# ESP32-P4 register map
Vendor: ESPRESSIF SYSTEMS (SHANGHAI) CO., LTD.; Series: ESP32 P-Series; File version: 3
CPU: RV32IMAFC r0p0, little endian, no MPU, FPU, 0 interrupt priority bits
Address unit: 32 bits
Registers are 32-bit, read-write, reset 0x0 unless marked. A register's access mark holds for its fields unless they carry their own. Offsets are from the block's base; [hi:lo] are bit positions; lines under a group give offsets from that group; {n}, {i} and the like mark numbered series; 'fields as' and 'values as' point back to an identical list.

## MEMSPI3 — Memory SPI 3
Base 0x5008F000
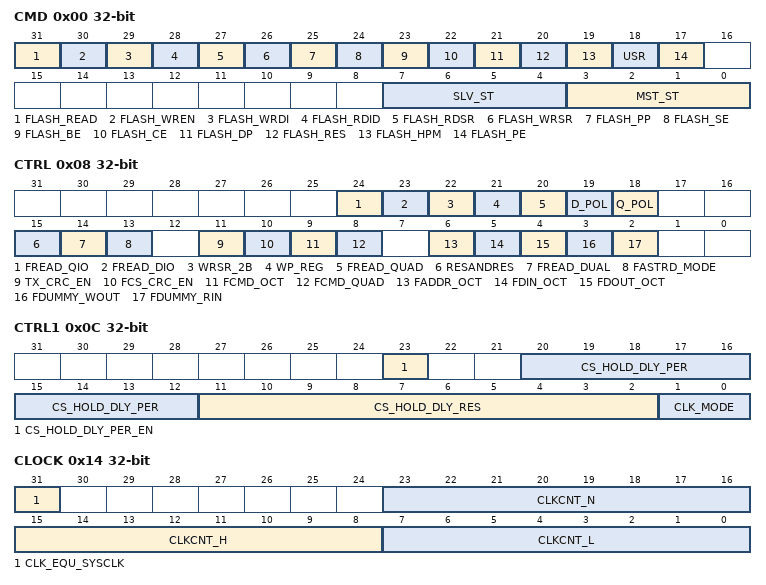
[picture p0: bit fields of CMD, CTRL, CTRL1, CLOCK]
0x00 CMD access per field
  [31] FLASH_READ rw, [30] FLASH_WREN rw, [29] FLASH_WRDI rw, [28] FLASH_RDID rw, [27] FLASH_RDSR rw, [26] FLASH_WRSR rw, [25] FLASH_PP rw, [24] FLASH_SE rw, [23] FLASH_BE rw, [22] FLASH_CE rw, [21] FLASH_DP rw, [20] FLASH_RES rw, [19] FLASH_HPM rw, [18] USR rw, [17] FLASH_PE rw, [7:4] SLV_ST ro, [3:0] MST_ST ro
0x04 ADDR
  [31:0] USR_ADDR_VALUE
0x08 CTRL
  [24] FREAD_QIO, [23] FREAD_DIO, [22] WRSR_2B, [21] WP_REG, [20] FREAD_QUAD, [19] D_POL, [18] Q_POL, [15] RESANDRES, [14] FREAD_DUAL, [13] FASTRD_MODE, [11] TX_CRC_EN, [10] FCS_CRC_EN, [9] FCMD_OCT, [8] FCMD_QUAD, [6] FADDR_OCT, [5] FDIN_OCT, [4] FDOUT_OCT, [3] FDUMMY_WOUT, [2] FDUMMY_RIN
0x0C CTRL1
  [23] CS_HOLD_DLY_PER_EN, [20:12] CS_HOLD_DLY_PER, [11:2] CS_HOLD_DLY_RES, [1:0] CLK_MODE
0x10 CTRL2 wo
  [31] SYNC_RESET
0x14 CLOCK
  [31] CLK_EQU_SYSCLK, [23:16] CLKCNT_N, [15:8] CLKCNT_H, [7:0] CLKCNT_L
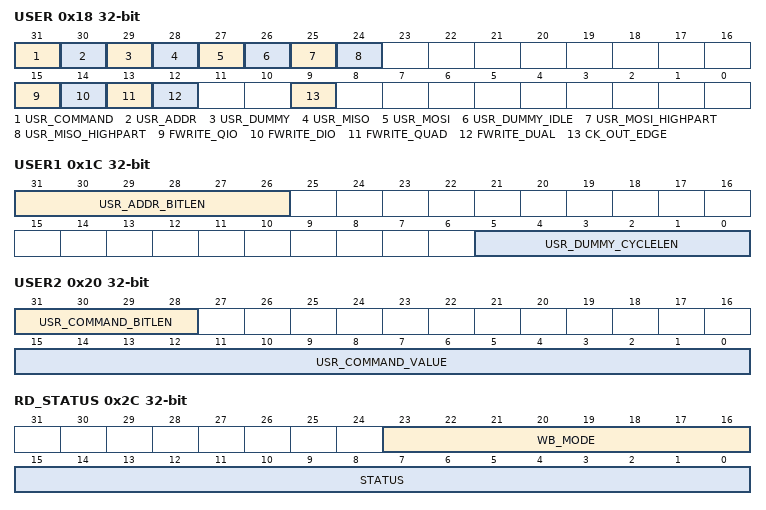
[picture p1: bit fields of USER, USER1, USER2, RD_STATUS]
0x18 USER
  [31] USR_COMMAND, [30] USR_ADDR, [29] USR_DUMMY, [28] USR_MISO, [27] USR_MOSI, [26] USR_DUMMY_IDLE, [25] USR_MOSI_HIGHPART, [24] USR_MISO_HIGHPART, [15] FWRITE_QIO, [14] FWRITE_DIO, [13] FWRITE_QUAD, [12] FWRITE_DUAL, [9] CK_OUT_EDGE
0x1C USER1
  [31:26] USR_ADDR_BITLEN, [5:0] USR_DUMMY_CYCLELEN
0x20 USER2
  [31:28] USR_COMMAND_BITLEN, [15:0] USR_COMMAND_VALUE
0x24 MOSI_DLEN
  [9:0] USR_MOSI_DBITLEN
0x28 MISO_DLEN
  [9:0] USR_MISO_DBITLEN
0x2C RD_STATUS
  [23:16] WB_MODE, [15:0] STATUS
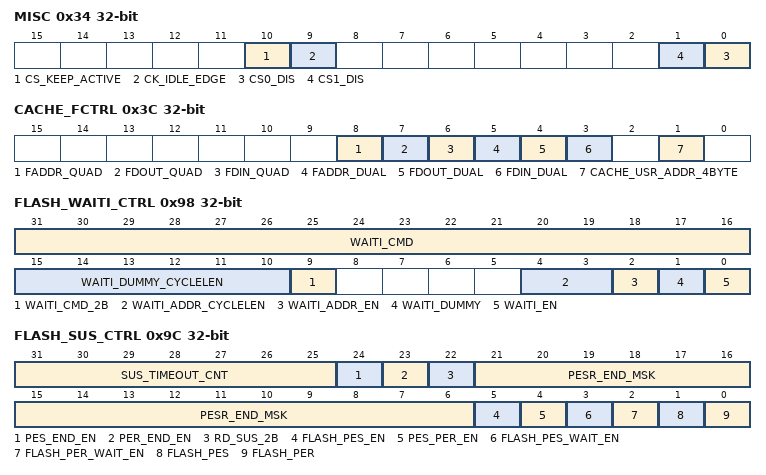
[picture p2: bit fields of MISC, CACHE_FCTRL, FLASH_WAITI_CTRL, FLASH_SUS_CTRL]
0x34 MISC
  [10] CS_KEEP_ACTIVE, [9] CK_IDLE_EDGE, [n] CS{n}_DIS (n=0..1)
0x38 TX_CRC ro
  [31:0] DATA
0x3C CACHE_FCTRL
  [8] FADDR_QUAD, [7] FDOUT_QUAD, [6] FDIN_QUAD, [5] FADDR_DUAL, [4] FDOUT_DUAL, [3] FDIN_DUAL, [1] CACHE_USR_ADDR_4BYTE
{0x58+4i} W{i} (i=0..15) reset 0xFFFFFFFF
  [31:0] BUF
0x98 FLASH_WAITI_CTRL
  [31:16] WAITI_CMD, [15:10] WAITI_DUMMY_CYCLELEN, [9] WAITI_CMD_2B, [4:3] WAITI_ADDR_CYCLELEN, [2] WAITI_ADDR_EN, [1] WAITI_DUMMY, [0] WAITI_EN
0x9C FLASH_SUS_CTRL
  [31:25] SUS_TIMEOUT_CNT, [24] PES_END_EN, [23] PER_END_EN, [22] RD_SUS_2B, [21:6] PESR_END_MSK, [5] FLASH_PES_EN, [4] PES_PER_EN, [3] FLASH_PES_WAIT_EN, [2] FLASH_PER_WAIT_EN, [1] FLASH_PES, [0] FLASH_PER
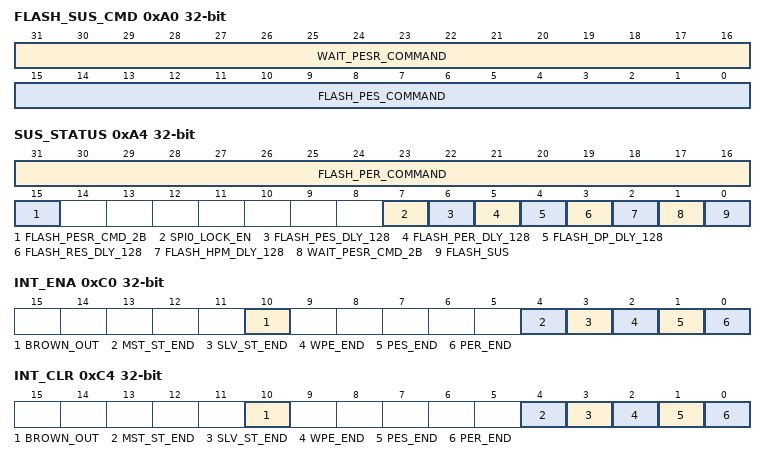
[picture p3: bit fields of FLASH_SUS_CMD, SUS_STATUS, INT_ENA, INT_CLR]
0xA0 FLASH_SUS_CMD
  [31:16] WAIT_PESR_COMMAND, [15:0] FLASH_PES_COMMAND
0xA4 SUS_STATUS
  [31:16] FLASH_PER_COMMAND, [15] FLASH_PESR_CMD_2B, [7] SPI0_LOCK_EN, [6] FLASH_PES_DLY_128, [5] FLASH_PER_DLY_128, [4] FLASH_DP_DLY_128, [3] FLASH_RES_DLY_128, [2] FLASH_HPM_DLY_128, [1] WAIT_PESR_CMD_2B, [0] FLASH_SUS
0xC0 INT_ENA
  [10] BROWN_OUT, [4] MST_ST_END, [3] SLV_ST_END, [2] WPE_END, [1] PES_END, [0] PER_END
0xC4 INT_CLR wo
  [10] BROWN_OUT write-1-clears, [4] MST_ST_END write-1-clears, [3] SLV_ST_END write-1-clears, [2] WPE_END write-1-clears, [1] PES_END write-1-clears, [0] PER_END write-1-clears
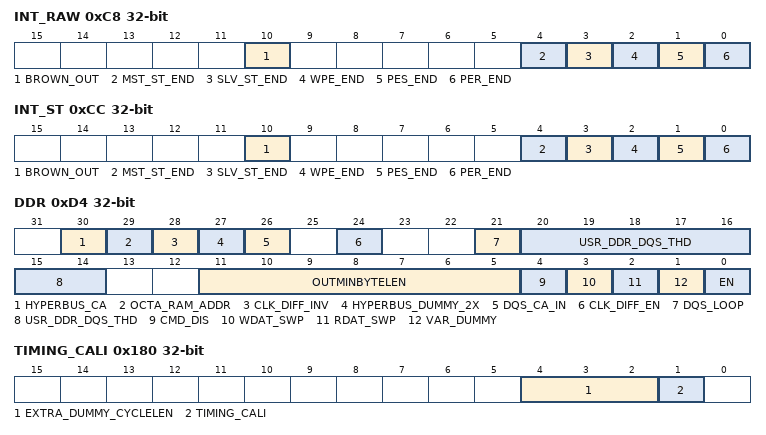
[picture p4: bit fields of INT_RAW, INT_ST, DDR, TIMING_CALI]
0xC8 INT_RAW
  fields as INT_ENA
0xCC INT_ST ro
  fields as INT_ENA
0xD4 DDR
  [30] HYPERBUS_CA, [29] OCTA_RAM_ADDR, [28] CLK_DIFF_INV, [27] HYPERBUS_DUMMY_2X, [26] DQS_CA_IN, [24] CLK_DIFF_EN, [21] DQS_LOOP, [20:14] USR_DDR_DQS_THD, [11:5] OUTMINBYTELEN, [4] CMD_DIS, [3] WDAT_SWP, [2] RDAT_SWP, [1] VAR_DUMMY, [0] EN
0x180 TIMING_CALI
  [4:2] EXTRA_DUMMY_CYCLELEN, [1] TIMING_CALI
0x200 CLOCK_GATE
  [0] CLK_EN
0x3FC DATE
  [27:0] DATE

## SYSTIMER — System Timer
Base 0x500E2000
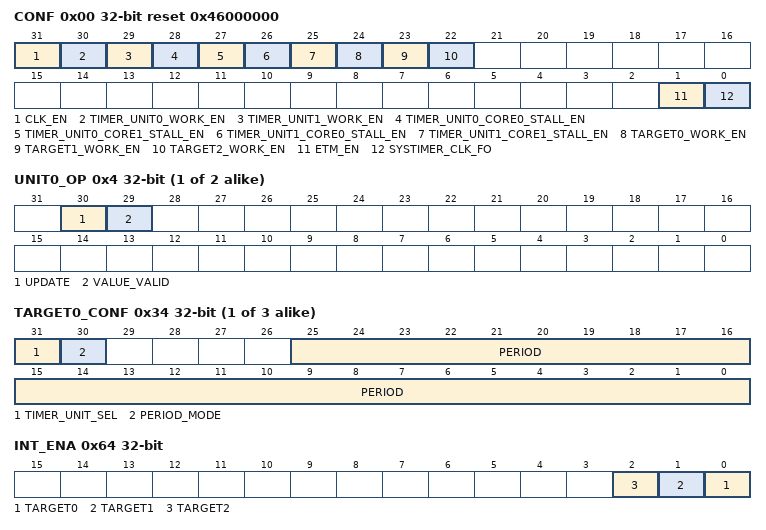
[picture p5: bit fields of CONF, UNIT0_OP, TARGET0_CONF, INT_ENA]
0x00 CONF reset 0x46000000 — Configure system timer clock
  [31] CLK_EN — register file clk gating
  [30] TIMER_UNIT0_WORK_EN — timer unit0 work enable
  [29] TIMER_UNIT1_WORK_EN — timer unit1 work enable
  [28] TIMER_UNIT0_CORE0_STALL_EN — If timer unit0 is stalled when core0 stalled
  [27] TIMER_UNIT0_CORE1_STALL_EN — If timer unit0 is stalled when core1 stalled
  [26] TIMER_UNIT1_CORE0_STALL_EN — If timer unit1 is stalled when core0 stalled
  [25] TIMER_UNIT1_CORE1_STALL_EN — If timer unit1 is stalled when core1 stalled
  [24] TARGET0_WORK_EN — target0 work enable
  [23] TARGET1_WORK_EN — target1 work enable
  [22] TARGET2_WORK_EN — target2 work enable
  [1] ETM_EN — enable systimer's etm task and event
  [0] SYSTIMER_CLK_FO — systimer clock force on
{0x4+4i} UNIT{i}_OP (i=0..1) access per field — system timer unit{i} value update register
  [30] UPDATE wo — update timer_unit0
  [29] VALUE_VALID ro — timer value is sync and valid
{0xC+8i} UNIT{i}LOAD (i=0..1) group — Cluster UNIT{i}LOAD, containing UNIT?_LOAD_HI, UNIT?_LOAD_LO
  0x00 HI — system timer unit0 value high load register
    [19:0] LOAD_HI — timer unit0 load high 20 bits
  0x04 LO — system timer unit0 value low load register
    [31:0] LOAD_LO — timer unit0 load low 32 bits
{0x1C+8i} TRGT{i} (i=0..2) group — Cluster TRGT{i}, containing TARGET?_HI, TARGET?_LO
  0x00 HI — system timer comp0 value high register
    [19:0] HI — timer taget0 high 20 bits
  0x04 LO — system timer comp0 value low register
    [31:0] LO — timer taget0 low 32 bits
{0x34+4i} TARGET{i}_CONF (i=0..2) — system timer comp{i} target mode register
  [31] TIMER_UNIT_SEL — select which unit to compare
  [30] PERIOD_MODE — Set target0 to period mode
  [25:0] PERIOD — target0 period
{0x40+8i} UNIT{i}_VALUE (i=0..1) group — Cluster UNIT{i}_VALUE, containing UNIT?_VALUE_HI, UNIT?_VALUE_LO
  0x00 HI ro — system timer unit0 value high register
    [19:0] VALUE_HI — timer read value high 20bits
  0x04 LO ro — system timer unit0 value low register
    [31:0] VALUE_LO — timer read value low 32bits
{0x50+4i} COMP{i}_LOAD (i=0..2) wo — system timer comp{i} conf sync register
  [0] LOAD — timer comp0 sync enable signal
{0x5C+4i} UNIT{i}_LOAD (i=0..1) wo — system timer unit{i} conf sync register
  [0] LOAD — timer unit0 sync enable signal
0x64 INT_ENA — systimer interrupt enable register
  [n] TARGET{n} (n=0..2) — interupt{n} enable
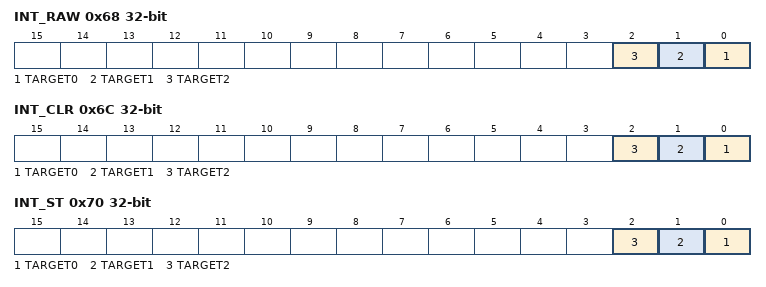
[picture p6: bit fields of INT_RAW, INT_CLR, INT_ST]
0x68 INT_RAW — systimer interrupt raw register
  [n] TARGET{n} (n=0..2) — interupt{n} raw
0x6C INT_CLR wo — systimer interrupt clear register
  [n] TARGET{n} (n=0..2) write-1-clears — interupt{n} clear
0x70 INT_ST ro — systimer interrupt status register
  [n] TARGET{n} (n=0..2) — interupt{n} status
{0x74+8i} REAL_TARGET{i} (i=0..2) group — Cluster REAL_TARGET{i}, containing REAL_TARGET?_LO, REAL_TARGET?_HI
  0x00 LO ro — system timer comp0 actual target value low register
    [31:0] LO_RO — actual target value value low 32bits
  0x04 HI ro — system timer comp0 actual target value high register
    [19:0] HI_RO — actual target value value high 20bits
0xFC DATE reset 0x2201073 — system timer version control register
  [31:0] DATE — systimer register version
